# RL7005_IP_SVD register map
Vendor: Realtek
Registers are 32-bit, read-write, reset 0x0 unless marked. A register's access mark holds for its fields unless they carry their own. Offsets are from the block's base; [hi:lo] are bit positions.

## UART0_REG
Base 0x4080C000
Same registers: UART1_REG 0x4080D000, UART2_REG 0x4080E000, UART3_REG 0x4080F000
0x00 UART_DLL — UART divisor length register
  [7:0] BAUD — The low 8 bits of divisor coefficient (not used)
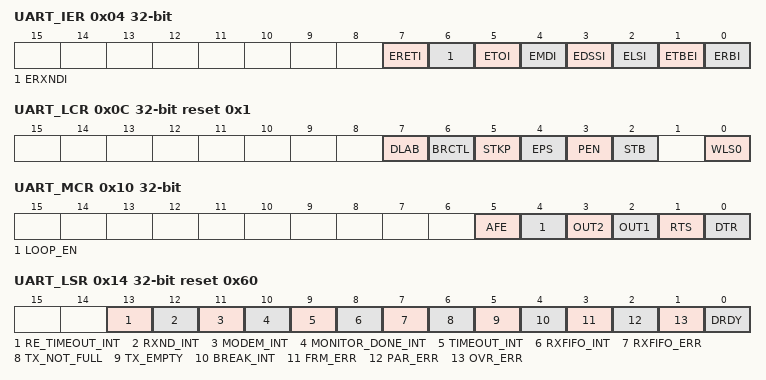
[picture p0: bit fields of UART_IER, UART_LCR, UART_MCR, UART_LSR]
0x04 UART_IER — UART interrupt enable register
  [7] ERETI — RXFIFO_EMPTY_TIMEOUT interrupt enable
  [6] ERXNDI — Rx noise detected interrupt enable
  [5] ETOI — Rx timeout interrupt enable
  [4] EMDI — Rx path monitor done interrupt enable
  [3] EDSSI — Modem Status Interrupt (EDSSI) (modem status transition) enable
  [2] ELSI — Receiver Line Status Interrupt (ELSI) (receiver line status) enable
  [1] ETBEI — Transmitter FIFO Empty interrupt (ETBEI) (Tx FIFO empty) enable
  [0] ERBI — Received Data Available Interrupt (ERBFI) (Rx trigger) enable
0x08 UART_IIR ro reset 0x1 — UART interrupt identification register
  [0] INT_PEND — * 0: pending, and the IIR contents may be used as a pointer to the appropriate interrupt service routine * 1: no interrupt is pending
0x0C UART_LCR reset 0x1 — UART line control register
  [7] DLAB — Divisor Latch Access bit, and control the accessibility of the DLL, DLM and IER registers * 0: The divisor latches not accessible; IER accessible * 1: The divisor latches accessible; DLL and DLM accessible Note: THR/RBR don't care the value of dlab bit.
  [6] BRCTL — Break Control bit * 0: break signal disable * 1: break signal enable (logic '0')
  [5] STKP — Stick Parity bit * 0: Not stick parity, the parity type is ODD or EVEN (depending on eps) * 1: Stick parity **eps=1: low parity (1'b0) **eps=0: high parity (1'b1)
  [4] EPS — Even Parity selection * 0: Odd parity, the number of Logic '1' is odd * 1: Even parity, the number of Logic '1' is even
  [3] PEN — Parity Enable * 0: No parity bit * 1: Parity bit is generated on each outgoing character and is checked on each incoming one
  [2] STB — Stop bits length selection * 0: 1 stop bit * 1: 2 stop bits Note: The receiver always checks the first stop bit only.
  [0] WLS0 — Word length selection * 0: 7 bits data * 1: 8 bits data
0x10 UART_MCR — UART modem control register
  [5] AFE — Auto flow control enable
  [4] LOOP_EN — LoopBack mode * 0: Normal operation mode * 1: Loopback mode
  [3] OUT2 — Auxiliary output 2 Bit[3] affects the OUT2_ output in a manner identical to that described above set to 0 In loopback mode, connected to Data Carrier Detect (DCD).
  [2] OUT1 — Auxiliary output 1 Bit3 affects the OUT1_ output in a manner identical to that described above set to 0 In loopback mode, connected to Ring Indicator (RI)
  [1] RTS — Request to Send (RTS) signal control * 0: rts is logic 1. * 1: rts is logic 0. This bit controls the RTS_ output. Bit[1] affects the RTS_ output in a manner identical to that described above set to 0.
  [0] DTR — * 0: dtr is logic 1 * 1: dtr is logic 0 This bit controls the DTR output
0x14 UART_LSR ro reset 0x60 — UART line status register
  [13] RE_TIMEOUT_INT — This bit is only set when rxfifo empty timeout interrupt is enabled(ERETI is set) 1:Rxfifo is empty for longer than TH_RETI
  [12] RXND_INT — This bit is only set when RX debouncer has detected noise 1: Rx path noise detected interrupt
  [11] MODEM_INT — This bit is only set when Modem status pending 1: Modem interrupt
  [10] MONITOR_DONE_INT — This bit is only set when Rx Path Monitor Done interrupt is enabled(EMDI is set) 1: Rx path monitor done
  [9] TIMEOUT_INT — This bit is only set when Rx Timeout interrupt is enabled(ETOI is set) 1: at least one character in the FIFO but no character has been input to the FIFO or reading from it for the time duration, which depends on the value in register REG_RX_PATH_CTRL[31:16]
  [8] RXFIFO_INT — This bit is only set when Received Data Available Interrupt interrupt is enabled(ERBI is set) 1: FIFO Trigger level reached or Rx FIFO full
  [7] RXFIFO_ERR — Uart_rx_error, depending on the FIFO control register (FCR) bit[0] * 0: clear when the CPU reads the LSR, if there are no subsequent errors in the FIFO. * 1: parity error, overrun error, framing error or break indication in the FIFO.
  [6] TX_NOT_FULL — TXFIFO not full indicator
  [5] TX_EMPTY — TXFIFO empty indicator
  [4] BREAK_INT — Break Interrupt (BI) indicator * 0: No break condition in the current character * 1: The received data input held in the Spacing ( logic 0) state is longer than a full word transmission time
  [3] FRM_ERR — Framing Error (FE) indicator * 0: No framing error in the current character * 1: The received character does not have a valid stop bit
  [2] PAR_ERR — Parity Error (PE) indicator * 0: No parity error in current character * 1: The received character does not have the correct parity bit
  [1] OVR_ERR — Overrun Error (OE) indicator * 0: No Overrun state * 1: The transmission is continue although the Rx FIFO is full
  [0] DRDY — * 0: No characters in the Receiver FIFO * 1: At least one character has been received and transferred into the FIFO
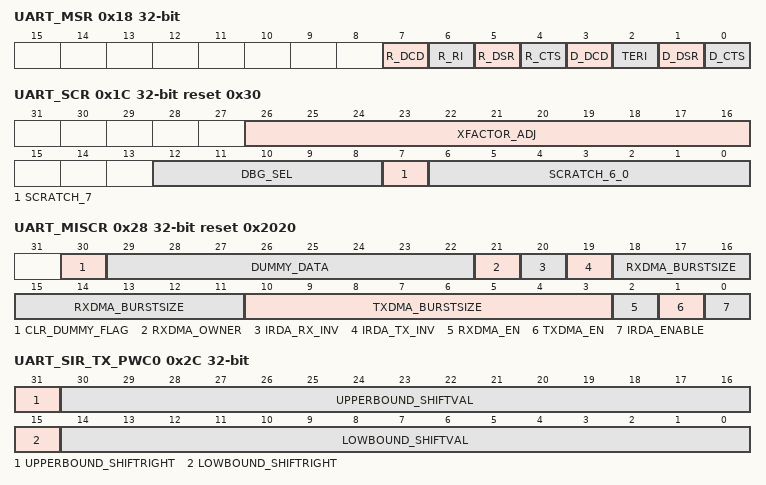
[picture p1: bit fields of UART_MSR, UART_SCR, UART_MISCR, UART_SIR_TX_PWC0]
0x18 UART_MSR ro — UART modem status register
  [7] R_DCD — Complement of the DCD input or equals to Out2 in loopback mode.
  [6] R_RI — Complement of the RI input or equals to Out1 in loopback mode.
  [5] R_DSR — Complement of the DSR input or equals to DTR in loopback mode.
  [4] R_CTS — Complement of the CTS input or equals to RTS in loopback mode.
  [3] D_DCD — * 0: Otherwise * 1: The DCD line has changed its state
  [2] TERI — * 0: Otherwise * 1: The RI line has changed its state from low to high state
  [1] D_DSR — * 0: Otherwise * 1: The DSR line has changed its state
  [0] D_CTS — * 0: Otherwise * 1: The CTS line has changed its state
0x1C UART_SCR reset 0x30 — UART scratch pad register
  [26:16] XFACTOR_ADJ — One factor of Baud rate calculation for TX path
  [12:8] DBG_SEL — Debug port selection
  [7] SCRATCH_7 — clear rx break signal interrupt status
  [6:0] SCRATCH_6_0 — *Bit[6]: rx break signal interrupt enable *Bit[5]: fl_set_bi_err *Bit[4]: fl_frame_err *Bit[3]: pin_lb_test *Bit[2:0]: reserved
0x20 UART_STS reset 0x10470
  [23:4] XFACTOR — Factor of Baud rate calculation for Tx path
0x24 UART_RBR_OR_UART_THR — UART receiver buffer register/UART transmitter holding register
  [7:0] DATABIT — UART_RBR's Rx data bits or UART_THR's Tx data bit[7:0] Note: Bit[0] is the least significant bit. It is the first bit serially received/transmitted.
0x28 UART_MISCR access per field reset 0x2020 — UART MISC control register
  [30] CLR_DUMMY_FLAG wo — Indicate the clearing of dummy data
  [29:22] DUMMY_DATA rw — Store dummy data, when UART is DMA flow controller, dummy data is padded for last RXDMA burst request.
  [21] RXDMA_OWNER rw — * 0: GDMA * 1: UART, interrupt enable signal other than erpd should be masked
  [20] IRDA_RX_INV rw — irda_rx_i reverse input enable
  [19] IRDA_TX_INV rw — irda_tx_o reverse output enable
  [18:11] RXDMA_BURSTSIZE rw — RXDMA burstsize, maximum value is 16.
  [10:3] TXDMA_BURSTSIZE rw — TXDMA burstsize, maximum value is 16.
  [2] RXDMA_EN rw — RXDMA enable, valid when dma_mode in FCR is 1'b1
  [1] TXDMA_EN rw — TXDMA enable, valid when dma_mode in FCR is 1'b1
  [0] IRDA_ENABLE rw — * 0: UART mode only * 1: UART is co-work with IRDA SIR mode
0x2C UART_SIR_TX_PWC0 — UART IRDA SIR TX pulse width control 0 register
  [31] UPPERBOUND_SHIFTRIGHT — * 0: Shift left, minus offset value of upperbound_shiftval * 1: Shift right, plus offset value of upperbound_shiftval
  [30:16] UPPERBOUND_SHIFTVAL — The shift value of SIR TX pulse's right edge
  [15] LOWBOUND_SHIFTRIGHT — * 0: Shift left, minus offset value of lowbound_shiftval * 1: Shift right, plus offset value of lowbound_shiftval
  [14:0] LOWBOUND_SHIFTVAL — The shift value of SIR TX pulse's left edge
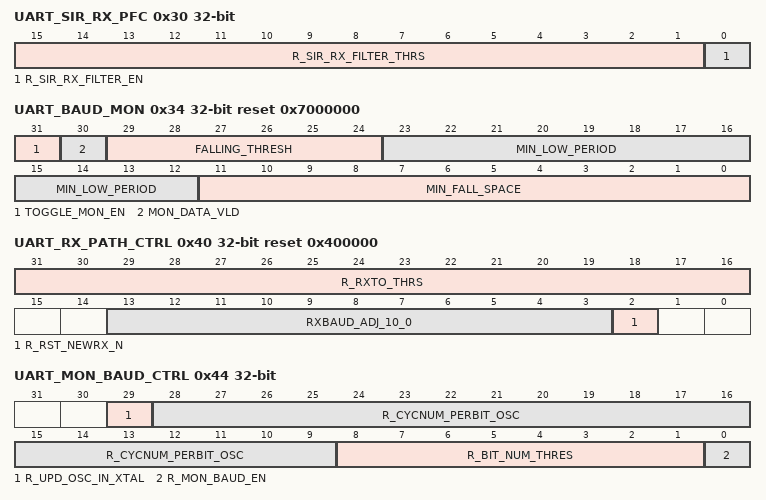
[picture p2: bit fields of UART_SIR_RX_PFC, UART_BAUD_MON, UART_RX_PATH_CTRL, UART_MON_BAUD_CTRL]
0x30 UART_SIR_RX_PFC — UART IRDA SIR Rx pulse filter control register
  [15:1] R_SIR_RX_FILTER_THRS — The threshold of SIR Rx filter, Rx pulse is valid only when Rx pulse width is larger than the threshold.
  [0] R_SIR_RX_FILTER_EN — IrDA SIR Rx filter enable
0x34 UART_BAUD_MON access per field reset 0x7000000 — UART baud monitor register
  [31] TOGGLE_MON_EN rw — Toggle monitor enable
  [30] MON_DATA_VLD ro — Indicate valid monitoring data
  [29:24] FALLING_THRESH rw — Indicate the threshold of Rx data rising edge
  [23:12] MIN_LOW_PERIOD ro — Minimum space of consecutive logic '0' of Rx data
  [11:0] MIN_FALL_SPACE ro — Minimum space of adjacent falling edge of Rx data
0x3C UART_DBGR ro — UART debug register
  [31:0] DBG_UART — The output value of debug port, depending on dbg_sel value in SCR[2:0]
0x40 UART_RX_PATH_CTRL reset 0x400000 — UART Rx path control register
  [31:16] R_RXTO_THRS — Indicate the timeout threshold of Rx path, unit in one-bit time
  [13:3] RXBAUD_ADJ_10_0 — One factor of Baud rate calculation for Rx path, similar with xfactor_adj
  [2] R_RST_NEWRX_N — Reset new Rx path, low active
0x44 UART_MON_BAUD_CTRL — UART monitor baud rate control register
  [29] R_UPD_OSC_IN_XTAL — Update parameter r_cycnum_perbit_osc (during the update of parameter r_cycnum_perbit_xtal) enable
  [28:9] R_CYCNUM_PERBIT_OSC — Indicate the average OSC clock cycle number of one bit, for Rx path OSC clk NOTE: SW sets the initial value, HW updates it depending on the monitor result.
  [8:1] R_BIT_NUM_THRES — Indicate the bit number threshold of one monitor period, max value is 127
  [0] R_MON_BAUD_EN — Monitor Rx baud enable
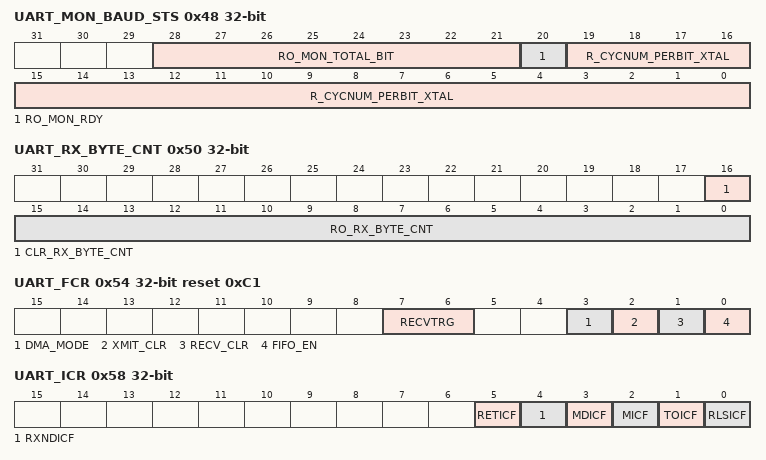
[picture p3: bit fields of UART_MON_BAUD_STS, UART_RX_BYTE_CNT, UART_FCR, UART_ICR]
0x48 UART_MON_BAUD_STS access per field — UART monitor baud rate status register
  [28:21] RO_MON_TOTAL_BIT ro — Indicate the number of bits actually monitored
  [20] RO_MON_RDY ro — Indicate the finish of calculation of actual cycle number per bit, it's cleared when r_mon_baud_en is 0
  [19:0] R_CYCNUM_PERBIT_XTAL rw — Indicate the fractional xtal clock cycle number of one bit, for Rx path xtal clk NOTE: SW sets the initial value, HW updates it depending on the monitor result.
0x4C UART_MON_CYC_NUM ro — UART monitored cycle number register
  [27:0] RO_MON_TOTAL_CYCLE — Indicate the number of clock cycle actually monitored
0x50 UART_RX_BYTE_CNT access per field — UART Rx data byte count register
  [16] CLR_RX_BYTE_CNT wo — Write 1 to clear ro_rx_byte_cnt
  [15:0] RO_RX_BYTE_CNT ro — Count the byte number of data read from rxfifo
0x54 UART_FCR access per field reset 0xC1 — UART FIFO control register
  [7:6] RECVTRG rw — Define the 16-entries Receiver FIFO Interrupt trigger level (0~15 bytes) * 00: 1 byte * 01: 16 bytes (FIFO_DEPTH/4) * 10: 32 bytes (FIFO_DEPTH/2) * 11: 62 bytes (FIFO_DEPTH-2)
  [3] DMA_MODE rw — Support dma mode (cooperate with DW DDMA in the data path)
  [2] XMIT_CLR wo — Clear xmitckt
  [1] RECV_CLR wo — Clear receiving
  [0] FIFO_EN rw — Error report of RCVR FIFO field enable, only valid when the LSR bit[7] is set to 1.
0x58 UART_ICR wo — UART interrupt clear register
  [5] RETICF — Rxfifo empty timeout Interrupt Clear Flag
  [4] RXNDICF — Rx noise Detected Interrupt Flag
  [3] MDICF — Monitor Done Interrupt Flag
  [2] MICF — Modem Interrupt Clear Flag
  [1] TOICF — Timeout Interrupt Clear Flag
  [0] RLSICF — Receiver Line Statue Interrupt Clear Flag Writing 1 to this bit clears PARITY_ERR, OVERRUN_ERR, FRAMING_ERR, BREAK_ERR_INT and RXFIFO_ERR in the USART_LSR register.
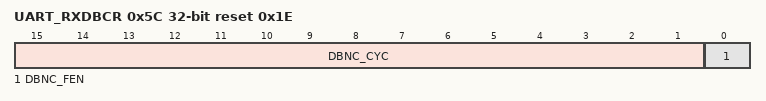
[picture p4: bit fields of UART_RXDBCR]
0x5C UART_RXDBCR reset 0x1E — UART RX debounce control register
  [15:1] DBNC_CYC — Debounce cycles in unit of sclk
  [0] DBNC_FEN — UART RX debounce enable
0x60 UART_TH_RETI — UART rxfifo empty interrupt timeout threshold
  [27:0] TH_RETI — Set rxfifo empty timeout interrupt, when rxfifo is empty for longer than TH_RETI. Timeout counter works in uart_rclk.
0x64 UART_DUMMY ro
  [15:0] dummy — rsvd for hw
